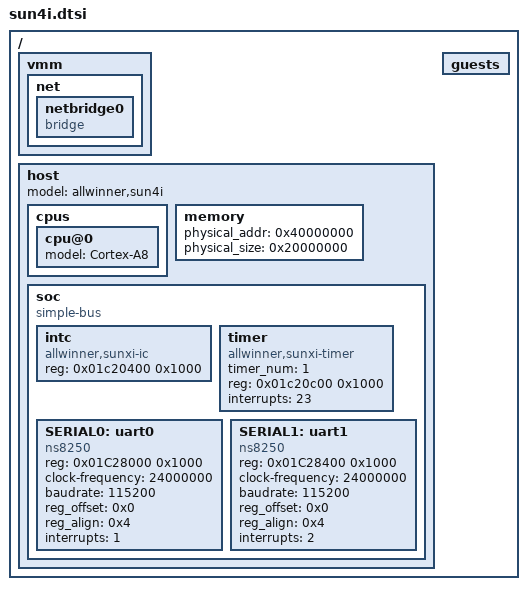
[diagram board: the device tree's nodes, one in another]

/ {
	vmm {
		net {
			netbridge0 {
				device_type = "netswitch";
				compatible = "bridge";
			};
		};
	};

	host {
		#address-cells = <1>;
		#size-cells = <1>;
		model = "allwinner,sun4i";
		device_type = "host";
		
		cpus {
			cpu@0 {
				device_type = "cpu";
				model = "Cortex-A8";
			};
		};

		memory {
			physical_addr = <0x40000000>;
			physical_size = <0x20000000>; /* 512 MB */
		};


		soc {
			#address-cells = <1>;
			#size-cells = <1>;
			compatible = "simple-bus";

			intc { /* Sun4i Vector Interrupt Controller */
		      		device_type = "pic";
		      		compatible = "allwinner,sunxi-ic";
		      		reg = <0x01c20400 0x1000>;
			};

			timer { /* Sun4i Timer Controller */
		      		device_type = "timer";
		      		compatible = "allwinner,sunxi-timer";
				timer_num = <1>; /* Timer1 */
		      		reg = <0x01c20c00 0x1000>;
				interrupts = <23>; /* Timer1 irq */
			};

			SERIAL0: uart0 { /* 8250 Serial Port */
				device_type = "serial";
				compatible = "ns8250";
				reg = <0x01C28000 0x1000>;
				clock-frequency = <24000000>;
				baudrate = <115200>;
				reg_offset = <0x0>;
				reg_align = <0x4>;
				interrupts = <1>;
			};

			SERIAL1: uart1 { /* 8250 Serial Port */
				device_type = "serial";
				compatible = "ns8250";
				reg = <0x01C28400 0x1000>;
				clock-frequency = <24000000>;
				baudrate = <115200>;
				reg_offset = <0x0>;
				reg_align = <0x4>;
				interrupts = <2>;
			};
		};
	};

	/* Empty guests node */
	guests {
	};
};

/* Add guest templates */
/include/ "../../common/guests/realview-pb-a8.dtsi"
/include/ "../../common/guests/vexpress-a9x2.dtsi"

